VERSION ""

NS_ :

BS_:

BU_: GWM VCU Tester

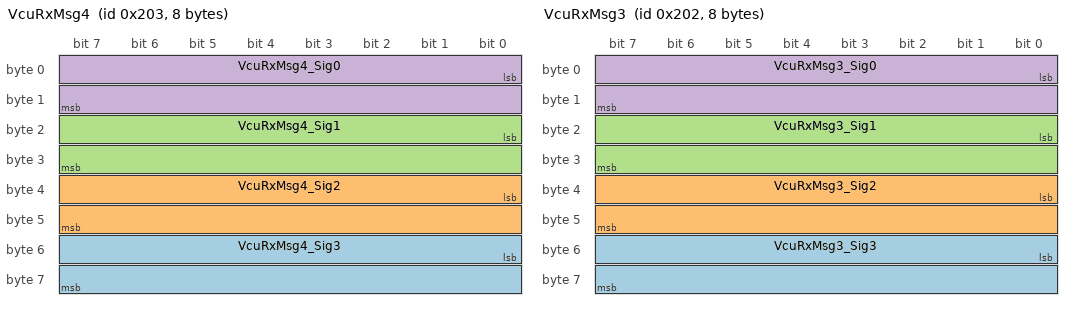
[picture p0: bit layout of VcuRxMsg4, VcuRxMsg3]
BO_ 515 VcuRxMsg4: 8 GWM
 SG_ VcuRxMsg4_Sig3 : 48|16@1- (1,0) [0|0] ""  VCU
 SG_ VcuRxMsg4_Sig2 : 32|16@1- (1,0) [0|0] ""  VCU
 SG_ VcuRxMsg4_Sig1 : 16|16@1- (1,0) [0|0] ""  VCU
 SG_ VcuRxMsg4_Sig0 : 0|16@1- (1,0) [0|0] ""  VCU

BO_ 514 VcuRxMsg3: 8 GWM
 SG_ VcuRxMsg3_Sig3 : 48|16@1- (1,0) [0|0] ""  VCU
 SG_ VcuRxMsg3_Sig2 : 32|16@1- (1,0) [0|0] ""  VCU
 SG_ VcuRxMsg3_Sig1 : 16|16@1- (1,0) [0|0] ""  VCU
 SG_ VcuRxMsg3_Sig0 : 0|16@1- (1,0) [0|0] ""  VCU

BO_ 273 VcuMeasurementMsg0: 8 VCU
 SG_ Ext_IN2 : 48|8@1- (1,0) [0|0] ""  GWM
 SG_ EXT_PWM_IN2_Duty : 40|8@1- (1,0) [0|0] "%"  GWM
 SG_ EXT_PWM_IN2_Period : 24|16@1- (1,0) [0|0] "us"  GWM
 SG_ EXT_PWM_IN1_Duty : 16|8@1- (1,0) [0|0] "%"  GWM
 SG_ EXT_PWM_IN1_Period : 0|16@1- (1,0) [0|0] "us"  GWM
 SG_ EXT_PWM_IN1_Period : 0|16@1- (1,0) [0|0] "us"  GWM

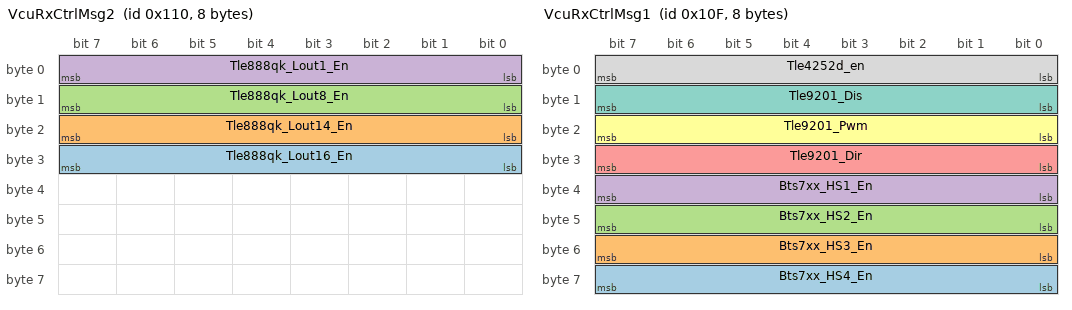
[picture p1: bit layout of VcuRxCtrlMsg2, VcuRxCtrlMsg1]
BO_ 272 VcuRxCtrlMsg2: 8 GW
 SG_ Tle888qk_Lout16_En : 24|8@1- (1,0) [0|0] ""  VCU
 SG_ Tle888qk_Lout14_En : 16|8@1- (1,0) [0|0] ""  VCU
 SG_ Tle888qk_Lout8_En : 8|8@1- (1,0) [0|0] ""  VCU
 SG_ Tle888qk_Lout1_En : 0|8@1- (1,0) [0|0] ""  VCU

BO_ 271 VcuRxCtrlMsg1: 8 GWM
 SG_ Bts7xx_HS4_En : 56|8@1- (1,0) [0|0] ""  VCU
 SG_ Bts7xx_HS3_En : 48|8@1- (1,0) [0|0] ""  VCU
 SG_ Bts7xx_HS2_En : 40|8@1- (1,0) [0|0] ""  VCU
 SG_ Bts7xx_HS1_En : 32|8@1- (1,0) [0|0] ""  VCU
 SG_ Tle9201_Dir : 24|8@1- (1,0) [0|0] ""  VCU
 SG_ Tle9201_Pwm : 16|8@1- (1,0) [0|0] ""  VCU
 SG_ Tle9201_Dis : 8|8@1- (1,0) [0|0] ""  VCU
 SG_ Tle4252d_en : 0|8@1- (1,0) [0|0] ""  VCU

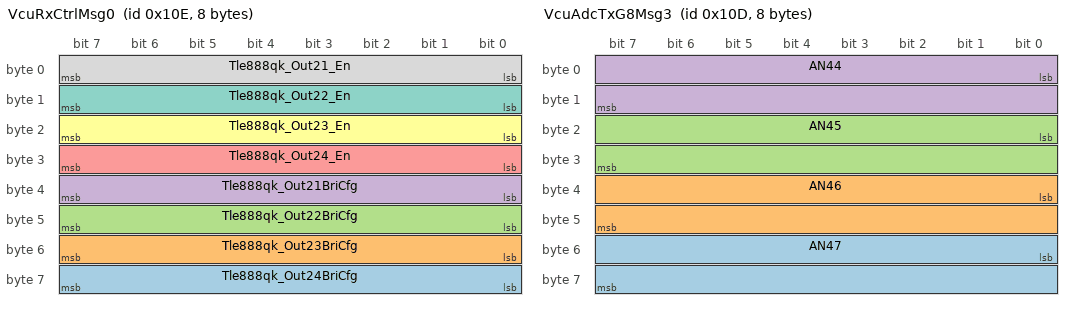
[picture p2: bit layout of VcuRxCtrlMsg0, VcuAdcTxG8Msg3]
BO_ 270 VcuRxCtrlMsg0: 8 GWM
 SG_ Tle888qk_Out24BriCfg : 56|8@1- (1,0) [0|0] ""  VCU
 SG_ Tle888qk_Out23BriCfg : 48|8@1- (1,0) [0|0] ""  VCU
 SG_ Tle888qk_Out22BriCfg : 40|8@1- (1,0) [0|0] ""  VCU
 SG_ Tle888qk_Out21BriCfg : 32|8@1- (1,0) [0|0] ""  VCU
 SG_ Tle888qk_Out24_En : 24|8@1- (1,0) [0|0] ""  VCU
 SG_ Tle888qk_Out23_En : 16|8@1- (1,0) [0|0] ""  VCU
 SG_ Tle888qk_Out22_En : 8|8@1- (1,0) [0|0] ""  VCU
 SG_ Tle888qk_Out21_En : 0|8@1- (1,0) [0|0] ""  VCU

BO_ 269 VcuAdcTxG8Msg3: 8 VCU
 SG_ AN47 : 48|16@1- (1,0) [0|0] "mV"  GWM
 SG_ AN46 : 32|16@1- (1,0) [0|0] "mV"  GWM
 SG_ AN45 : 16|16@1- (1,0) [0|0] "mV"  GWM
 SG_ AN44 : 0|16@1- (1,0) [0|0] "mV"  GWM

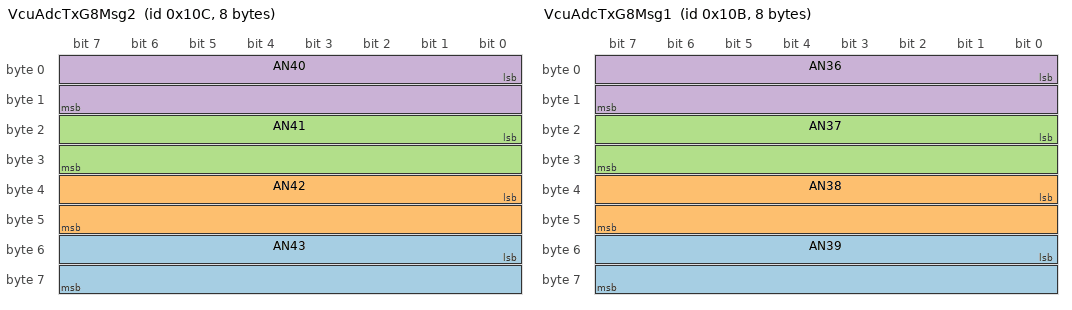
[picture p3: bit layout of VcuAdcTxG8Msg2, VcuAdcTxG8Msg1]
BO_ 268 VcuAdcTxG8Msg2: 8 VCU
 SG_ AN43 : 48|16@1- (1,0) [0|0] "mV"  GWM
 SG_ AN42 : 32|16@1- (1,0) [0|0] "mV"  GWM
 SG_ AN41 : 16|16@1- (1,0) [0|0] "mV"  GWM
 SG_ AN40 : 0|16@1- (1,0) [0|0] "mV"  GWM

BO_ 267 VcuAdcTxG8Msg1: 8 VCU
 SG_ AN39 : 48|16@1- (1,0) [0|0] "mV"  GWM
 SG_ AN38 : 32|16@1- (1,0) [0|0] "mV"  GWM
 SG_ AN37 : 16|16@1- (1,0) [0|0] "mV"  GWM
 SG_ AN36 : 0|16@1- (1,0) [0|0] "mV"  GWM

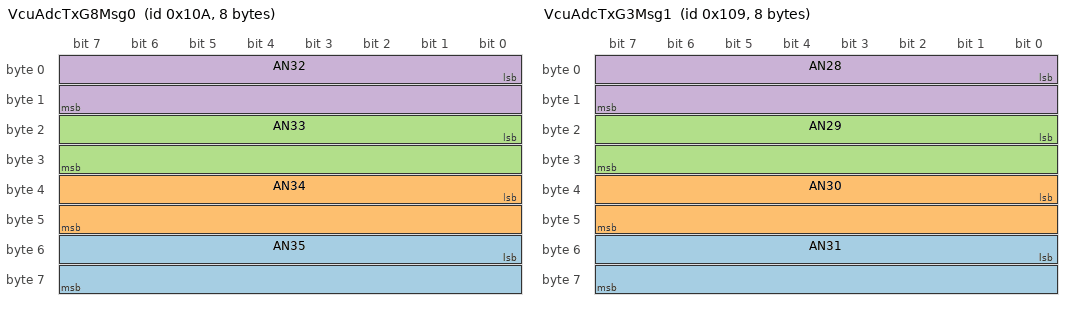
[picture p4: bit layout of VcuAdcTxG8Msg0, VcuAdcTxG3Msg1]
BO_ 266 VcuAdcTxG8Msg0: 8 VCU
 SG_ AN35 : 48|16@1- (1,0) [0|0] "mV"  GWM
 SG_ AN34 : 32|16@1- (1,0) [0|0] "mV"  GWM
 SG_ AN33 : 16|16@1- (1,0) [0|0] "mV"  GWM
 SG_ AN32 : 0|16@1- (1,0) [0|0] "mV"  GWM

BO_ 265 VcuAdcTxG3Msg1: 8 VCU
 SG_ AN31 : 48|16@1- (1,0) [0|0] "mV"  GWM
 SG_ AN30 : 32|16@1- (1,0) [0|0] "mV"  GWM
 SG_ AN29 : 16|16@1- (1,0) [0|0] "mV"  GWM
 SG_ AN28 : 0|16@1- (1,0) [0|0] "mV"  GWM

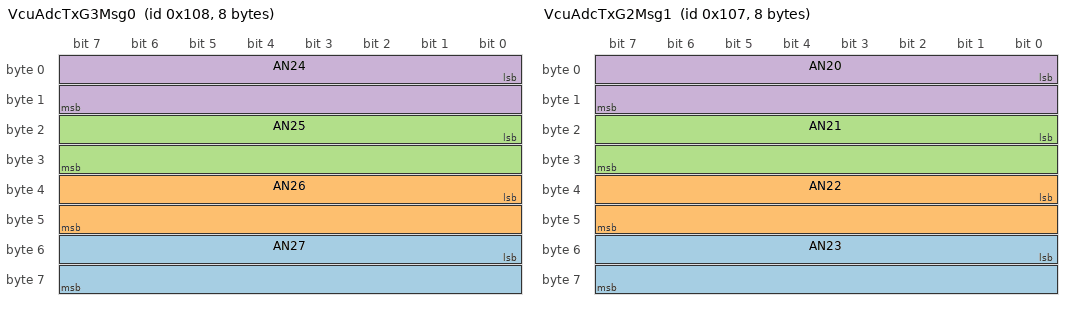
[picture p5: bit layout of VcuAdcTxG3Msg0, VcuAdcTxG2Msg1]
BO_ 264 VcuAdcTxG3Msg0: 8 VCU
 SG_ AN27 : 48|16@1- (1,0) [0|0] "mV"  GWM
 SG_ AN26 : 32|16@1- (1,0) [0|0] "mV"  GWM
 SG_ AN25 : 16|16@1- (1,0) [0|0] "mV"  GWM
 SG_ AN24 : 0|16@1- (1,0) [0|0] "mV"  GWM

BO_ 263 VcuAdcTxG2Msg1: 8 VCU
 SG_ AN23 : 48|16@1- (1,0) [0|0] "mV"  GWM
 SG_ AN22 : 32|16@1- (1,0) [0|0] "mV"  GWM
 SG_ AN21 : 16|16@1- (1,0) [0|0] "mV"  GWM
 SG_ AN20 : 0|16@1- (1,0) [0|0] "mV"  GWM

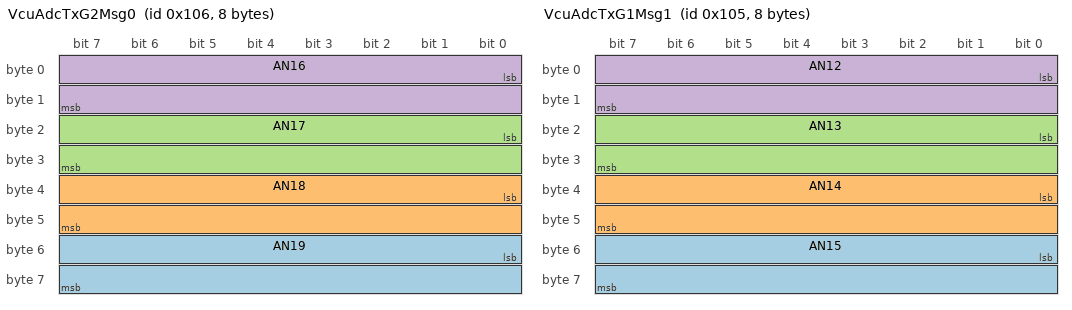
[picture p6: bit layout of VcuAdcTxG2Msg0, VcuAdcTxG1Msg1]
BO_ 262 VcuAdcTxG2Msg0: 8 VCU
 SG_ AN19 : 48|16@1- (1,0) [0|0] "mV"  GWM
 SG_ AN18 : 32|16@1- (1,0) [0|0] "mV"  GWM
 SG_ AN17 : 16|16@1- (1,0) [0|0] "mV"  GWM
 SG_ AN16 : 0|16@1- (1,0) [0|0] "mV"  GWM

BO_ 261 VcuAdcTxG1Msg1: 8 VCU
 SG_ AN15 : 48|16@1- (1,0) [0|0] "mV"  GWM
 SG_ AN14 : 32|16@1- (1,0) [0|0] "mV"  GWM
 SG_ AN13 : 16|16@1- (1,0) [0|0] "mV"  GWM
 SG_ AN12 : 0|16@1- (1,0) [0|0] "mV"  GWM

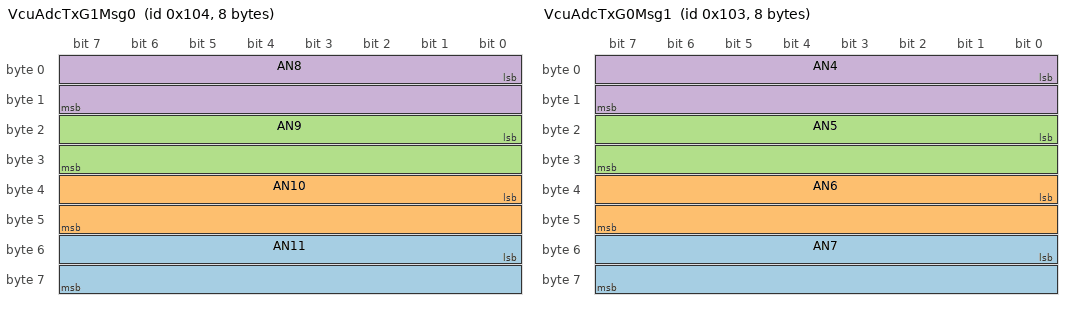
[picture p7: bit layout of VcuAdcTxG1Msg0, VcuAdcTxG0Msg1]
BO_ 260 VcuAdcTxG1Msg0: 8 VCU
 SG_ AN11 : 48|16@1- (1,0) [0|0] "mV"  GWM
 SG_ AN10 : 32|16@1- (1,0) [0|0] "mV"  GWM
 SG_ AN9 : 16|16@1- (1,0) [0|0] "mV"  GWM
 SG_ AN8 : 0|16@1- (1,0) [0|0] "mV"  GWM

BO_ 259 VcuAdcTxG0Msg1: 8 VCU
 SG_ AN7 : 48|16@1- (1,0) [0|0] "mV"  GWM
 SG_ AN6 : 32|16@1- (1,0) [0|0] "mV"  GWM
 SG_ AN5 : 16|16@1- (1,0) [0|0] "mV"  GWM
 SG_ AN4 : 0|16@1- (1,0) [0|0] "mV"  GWM

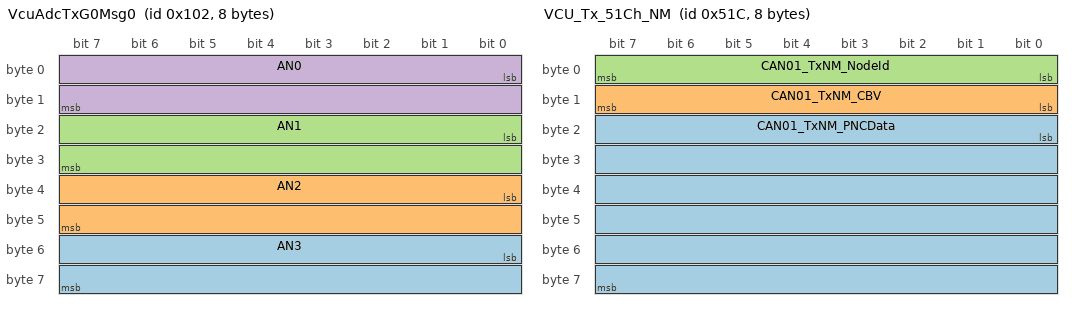
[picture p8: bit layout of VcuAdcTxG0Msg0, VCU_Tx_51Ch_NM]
BO_ 258 VcuAdcTxG0Msg0: 8 VCU
 SG_ AN3 : 48|16@1- (1,0) [0|0] "mV"  GWM
 SG_ AN2 : 32|16@1- (1,0) [0|0] "mV"  GWM
 SG_ AN1 : 16|16@1- (1,0) [0|0] "mV"  GWM
 SG_ AN0 : 0|16@1- (1,0) [0|0] "mV"  GWM

BO_ 1280 VCU_Rx_500h_NM: 8 GWM
 SG_ VCU_Rx_500h_NM : 0|64@1+ (1,0) [0|0] ""  VCU

BO_ 1308 VCU_Tx_51Ch_NM: 8 VCU
 SG_ CAN01_TxNM_PNCData : 16|48@1+ (1,0) [0|0] ""  ADCU_CH,CGW_CH
 SG_ CAN01_TxNM_CBV : 8|8@1+ (1,0) [0|0] ""  ADCU_CH,CGW_CH
 SG_ CAN01_TxNM_NodeId : 0|8@1+ (1,0) [0|0] ""  ADCU_CH,CGW_CH

BA_DEF_ BO_  "VFrameFormat" ENUM  "StandardCAN","ExtendedCAN","reserved","reserved","reserved","reserved","reserved","reserved","reserved","reserved","reserved","reserved","reserved","reserved","StandardCAN_FD","ExtendedCAN_FD";
BA_DEF_ BO_  "GenMsgCycleTime" INT 0 0;
BA_DEF_ BO_  "GenMsgSendType" ENUM  "Cyclic","NotUsed","NotUsed","NotUsed","NotUsed","NotUsed","NotUsed","IfActive","NoMsgSendType","NotUsed";
BA_DEF_ SG_  "GenSigSendType" ENUM  "Cyclic","OnWrite","OnWriteWithRepetition","OnChange","OnChangeWithRepetition","IfActive","IfActiveWithRepetition","NoSigSendType","NotUsed","NotUsed","NotUsed","NotUsed","NotUsed";
BA_DEF_  "Baudrate" INT 0 1000000;
BA_DEF_  "BusType" STRING ;
BA_DEF_  "NmType" STRING ;
BA_DEF_  "Manufacturer" STRING ;
BA_DEF_ BU_  "NodeLayerModules" STRING ;
BA_DEF_ BO_  "NmMessage" ENUM  "no","yes";
BA_DEF_  "NmAsrWaitBusSleepTime" INT 0 65535;
BA_DEF_  "NmAsrTimeoutTime" INT 1 65535;
BA_DEF_  "NmAsrRepeatMessageTime" INT 0 65535;
BA_DEF_ BU_  "NmAsrNodeIdentifier" HEX 0 255;
BA_DEF_ BU_  "NmAsrNode" ENUM  "no","yes";
BA_DEF_  "NmAsrMessageCount" INT 1 256;
BA_DEF_ BO_  "NmAsrMessage" ENUM  "no","yes";
BA_DEF_ BU_  "NmAsrCanMsgReducedTime" INT 1 65535;
BA_DEF_  "NmAsrCanMsgCycleTime" INT 1 65535;
BA_DEF_  "NmAsrBaseAddress" HEX 0 2047;
BA_DEF_ BU_  "ILUsed" ENUM  "no","yes";
BA_DEF_ BO_  "GenMsgILSupport" ENUM  "no","yes";
BA_DEF_  "DBName" STRING ;
BA_DEF_DEF_  "VFrameFormat" "ExtendedCAN_FD";
BA_DEF_DEF_  "GenMsgCycleTime" 0;
BA_DEF_DEF_  "GenMsgSendType" "Cyclic";
BA_DEF_DEF_  "GenSigSendType" "Cyclic";
BA_DEF_DEF_  "Baudrate" 500000;
BA_DEF_DEF_  "BusType" "";
BA_DEF_DEF_  "NmType" "";
BA_DEF_DEF_  "Manufacturer" "Vector";
BA_DEF_DEF_  "NodeLayerModules" " ";
BA_DEF_DEF_  "NmMessage" "no";
BA_DEF_DEF_  "NmAsrWaitBusSleepTime" 2000;
BA_DEF_DEF_  "NmAsrTimeoutTime" 2000;
BA_DEF_DEF_  "NmAsrRepeatMessageTime" 1500;
BA_DEF_DEF_  "NmAsrNodeIdentifier" 28;
BA_DEF_DEF_  "NmAsrNode" "yes";
BA_DEF_DEF_  "NmAsrMessageCount" 128;
BA_DEF_DEF_  "NmAsrMessage" "no";
BA_DEF_DEF_  "NmAsrCanMsgReducedTime" 320;
BA_DEF_DEF_  "NmAsrCanMsgCycleTime" 500;
BA_DEF_DEF_  "NmAsrBaseAddress" 1024;
BA_DEF_DEF_  "ILUsed" "yes";
BA_DEF_DEF_  "GenMsgILSupport" "yes";
BA_DEF_DEF_  "DBName" "";
BA_ "BusType" "CAN";
BA_ "NmType" "NmAsr";
BA_ "DBName" "TC37X_VCU_CAN01";
BA_ "VFrameFormat" BO_ 515 0;
BA_ "GenMsgCycleTime" BO_ 515 500;
BA_ "VFrameFormat" BO_ 514 0;
BA_ "GenMsgCycleTime" BO_ 514 500;
BA_ "GenMsgCycleTime" BO_ 269 500;
BA_ "VFrameFormat" BO_ 269 0;
BA_ "GenMsgCycleTime" BO_ 268 500;
BA_ "VFrameFormat" BO_ 268 0;
BA_ "GenMsgCycleTime" BO_ 267 500;
BA_ "VFrameFormat" BO_ 267 0;
BA_ "GenMsgCycleTime" BO_ 266 500;
BA_ "VFrameFormat" BO_ 266 0;
BA_ "GenMsgCycleTime" BO_ 265 500;
BA_ "VFrameFormat" BO_ 265 0;
BA_ "GenMsgCycleTime" BO_ 264 500;
BA_ "VFrameFormat" BO_ 264 0;
BA_ "GenMsgCycleTime" BO_ 263 500;
BA_ "VFrameFormat" BO_ 263 0;
BA_ "GenMsgCycleTime" BO_ 262 500;
BA_ "VFrameFormat" BO_ 262 0;
BA_ "GenMsgCycleTime" BO_ 261 500;
BA_ "VFrameFormat" BO_ 261 0;
BA_ "GenMsgCycleTime" BO_ 260 500;
BA_ "VFrameFormat" BO_ 260 0;
BA_ "VFrameFormat" BO_ 259 0;
BA_ "GenMsgCycleTime" BO_ 259 500;
BA_ "VFrameFormat" BO_ 258 0;
BA_ "GenMsgCycleTime" BO_ 258 500;
BA_ "VFrameFormat" BO_ 1280 0;
BA_ "GenMsgCycleTime" BO_ 1280 500;
BA_ "NmAsrMessage" BO_ 1280 1;
BA_ "NmMessage" BO_ 1280 1;
BA_ "VFrameFormat" BO_ 1308 0;
BA_ "GenMsgCycleTime" BO_ 1308 500;
BA_ "NmAsrMessage" BO_ 1308 1;
BA_ "NmMessage" BO_ 1308 1;
BA_ "GenMsgCycleTime" BO_ 270 500;
BA_ "VFrameFormat" BO_ 270 0;
BA_ "GenMsgCycleTime" BO_ 271 500;
BA_ "VFrameFormat" BO_ 271 0;
BA_ "GenMsgCycleTime" BO_ 272 500;
BA_ "VFrameFormat" BO_ 272 0;
BA_ "GenMsgCycleTime" BO_ 273 500;
BA_ "VFrameFormat" BO_ 273 0;
